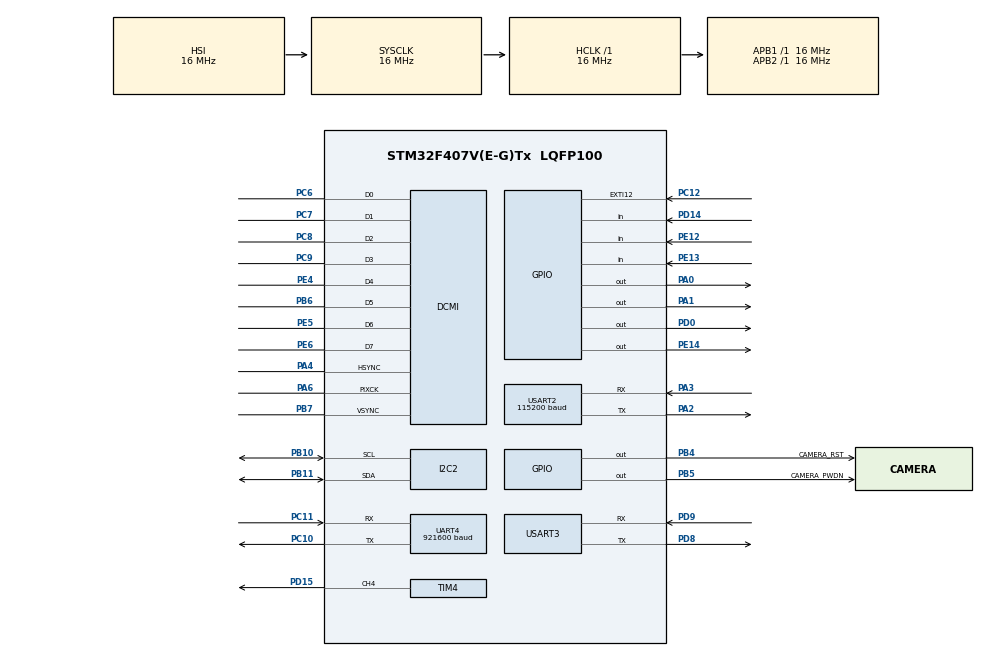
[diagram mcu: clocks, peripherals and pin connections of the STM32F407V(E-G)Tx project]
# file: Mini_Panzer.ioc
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DCMI.ExtendedDataMode=DCMI_EXTEND_DATA_8B
DCMI.SynchroMode=DCMI_SYNCHRO_HARDWARE
Dma.DCMI.2.Direction=DMA_PERIPH_TO_MEMORY
Dma.DCMI.2.FIFOMode=DMA_FIFOMODE_DISABLE
Dma.DCMI.2.Instance=DMA2_Stream1
Dma.DCMI.2.MemDataAlignment=DMA_MDATAALIGN_WORD
Dma.DCMI.2.MemInc=DMA_MINC_ENABLE
Dma.DCMI.2.Mode=DMA_NORMAL
Dma.DCMI.2.PeriphDataAlignment=DMA_PDATAALIGN_WORD
Dma.DCMI.2.PeriphInc=DMA_PINC_DISABLE
Dma.DCMI.2.Priority=DMA_PRIORITY_LOW
Dma.Request0=UART4_TX
Dma.Request1=UART4_RX
Dma.Request2=DCMI
Dma.UART4_RX.1.Direction=DMA_PERIPH_TO_MEMORY
Dma.UART4_RX.1.FIFOMode=DMA_FIFOMODE_DISABLE
Dma.UART4_RX.1.Instance=DMA1_Stream2
Dma.UART4_RX.1.MemDataAlignment=DMA_MDATAALIGN_BYTE
Dma.UART4_RX.1.MemInc=DMA_MINC_ENABLE
Dma.UART4_RX.1.Mode=DMA_NORMAL
Dma.UART4_RX.1.PeriphDataAlignment=DMA_PDATAALIGN_BYTE
Dma.UART4_RX.1.PeriphInc=DMA_PINC_DISABLE
Dma.UART4_RX.1.Priority=DMA_PRIORITY_VERY_HIGH
Dma.UART4_TX.0.Direction=DMA_MEMORY_TO_PERIPH
Dma.UART4_TX.0.FIFOMode=DMA_FIFOMODE_DISABLE
Dma.UART4_TX.0.Instance=DMA1_Stream4
Dma.UART4_TX.0.MemDataAlignment=DMA_MDATAALIGN_BYTE
Dma.UART4_TX.0.MemInc=DMA_MINC_ENABLE
Dma.UART4_TX.0.Mode=DMA_NORMAL
Dma.UART4_TX.0.PeriphDataAlignment=DMA_PDATAALIGN_BYTE
Dma.UART4_TX.0.PeriphInc=DMA_PINC_DISABLE
Dma.UART4_TX.0.Priority=DMA_PRIORITY_VERY_HIGH
FREERTOS.INCLUDE_xTaskAbortDelay=0
FREERTOS.INCLUDE_xTaskGetHandle=0
FREERTOS.MEMORY_ALLOCATION=0
FREERTOS.Tasks01=defaultTask,0,128,StartDefaultTask,Default
FREERTOS.configUSE_ALTERNATIVE_API=0
FREERTOS.configUSE_DAEMON_TASK_STARTUP_HOOK=0
I2C2.DutyCycle=I2C_DUTYCYCLE_2
Mcu.Family=STM32F4
Mcu.Name=STM32F407V(E-G)Tx
Mcu.Package=LQFP100
NVIC.DCMI_IRQn=true\:5\:0\:false\:false\:true\:true
NVIC.DMA1_Stream2_IRQn=true\:5\:0\:false\:false\:true\:true
NVIC.DMA1_Stream4_IRQn=true\:5\:0\:false\:false\:true\:true
NVIC.DMA2_Stream1_IRQn=true\:5\:0\:false\:false\:true\:true
NVIC.PriorityGroup=NVIC_PRIORITYGROUP_4
NVIC.UART4_IRQn=true\:5\:0\:false\:false\:true\:true
NVIC.USART2_IRQn=true\:5\:0\:false\:false\:true\:true
PA0-WKUP.GPIO_PuPd=GPIO_NOPULL
PA0-WKUP.GPIO_Speed=GPIO_SPEED_FREQ_VERY_HIGH
PA0-WKUP.PinState=GPIO_PIN_RESET
PA0-WKUP.Signal=GPIO_Output
PA1.GPIO_PuPd=GPIO_NOPULL
PA1.GPIO_Speed=GPIO_SPEED_FREQ_VERY_HIGH
PA1.PinState=GPIO_PIN_RESET
PA1.Signal=GPIO_Output
PA2.Mode=Asynchronous
PA2.Signal=USART2_TX
PA3.Mode=Asynchronous
PA3.Signal=USART2_RX
PA4.Mode=Slave_8_bits_External_Synchro
PA4.Signal=DCMI_HSYNC
PA6.Mode=Slave_8_bits_External_Synchro
PA6.Signal=DCMI_PIXCK
PB10.Mode=I2C
PB10.Signal=I2C2_SCL
PB11.Mode=I2C
PB11.Signal=I2C2_SDA
PB4.GPIO_Label=CAMERA_RST
PB4.GPIO_ModeDefaultOutputPP=GPIO_MODE_OUTPUT_PP
PB4.GPIO_PuPd=GPIO_NOPULL
PB4.PinState=GPIO_PIN_RESET
PB4.Signal=GPIO_Output
PB5.GPIO_Label=CAMERA_PWDN
PB5.Signal=GPIO_Output
PB6.Mode=Slave_8_bits_External_Synchro
PB6.Signal=DCMI_D5
PB7.Mode=Slave_8_bits_External_Synchro
PB7.Signal=DCMI_VSYNC
PC10.Mode=Asynchronous
PC10.Signal=UART4_TX
PC11.Mode=Asynchronous
PC11.Signal=UART4_RX
PC12.Signal=GPXTI12
PC6.Mode=Slave_8_bits_External_Synchro
PC6.Signal=DCMI_D0
PC7.Mode=Slave_8_bits_External_Synchro
PC7.Signal=DCMI_D1
PC8.Mode=Slave_8_bits_External_Synchro
PC8.Signal=DCMI_D2
PC9.Mode=Slave_8_bits_External_Synchro
PC9.Signal=DCMI_D3
PD0.Signal=GPIO_Output
PD14.Signal=GPIO_Input
PD15.Signal=S_TIM4_CH4
PD8.Mode=Asynchronous
PD8.Signal=USART3_TX
PD9.Mode=Asynchronous
PD9.Signal=USART3_RX
PE12.Signal=GPIO_Input
PE13.Signal=GPIO_Input
PE14.Signal=GPIO_Output
PE4.Mode=Slave_8_bits_External_Synchro
PE4.Signal=DCMI_D4
PE5.Mode=Slave_8_bits_External_Synchro
PE5.Signal=DCMI_D6
PE6.Mode=Slave_8_bits_External_Synchro
PE6.Signal=DCMI_D7
ProjectManager.HeapSize=0x200
ProjectManager.StackSize=0x400
ProjectManager.TargetToolchain=TrueSTUDIO
RCC.AHBFreq_Value=16000000
RCC.APB1Freq_Value=16000000
RCC.APB2Freq_Value=16000000
RCC.ClockTypeHCLK=RCC_CLOCKTYPE_HCLK
RCC.ClockTypePCLK1=RCC_CLOCKTYPE_PCLK1
RCC.ClockTypePCLK2=RCC_CLOCKTYPE_PCLK2
RCC.ClockTypeSysClk=RCC_CLOCKTYPE_SYSCLK
RCC.CortexFreq_Value=16000000
RCC.EnableExtClockForI2S=false
RCC.EnableHSE=false
RCC.EnableHSERTCDevisor=false
RCC.EnableLSE=false
RCC.EnableLSERTC=false
RCC.ExtClockEnable=false
RCC.HSEState=RCC_HSE_OFF
RCC.HSE_VALUE=25000000
RCC.HSIState=RCC_HSI_ON
RCC.HSI_VALUE=16000000
RCC.I2SEnable=false
RCC.IWDGEnable=false
RCC.LSE_VALUE=32768
RCC.LSIState=RCC_LSI_OFF
RCC.MCO1OutPutEnable=false
RCC.MCO2OutPutEnable=false
RCC.OscillatorTypeHSI=RCC_OSCILLATORTYPE_HSI
RCC.PLLSource=RCC_PLLSOURCE_HSI
RCC.PLLSourceVirtual=RCC_PLLSOURCE_HSI
RCC.PLLState=RCC_PLL_OFF
RCC.RNGEnable=false
RCC.RTCEnable=false
RCC.SDIOEnable=false
RCC.SYSCLKFreq_VALUE=16000000
RCC.USBFSEnable=false
RCC.USBHSEnable=false
RCC.VCOOutputFreq_Value=192000000
SH.S_TIM4_CH4.0=TIM4_CH4,PWM Generation4 CH4
TIM4.Channel-PWM\ Generation4\ CH4=TIM_CHANNEL_4
UART4.BaudRate=921600
UART4.VirtualMode=Asynchronous
USART2.BaudRate=115200
USART2.HwFlowCtl-Asynchronous=UART_HWCONTROL_NONE
USART2.OverSampling=UART_OVERSAMPLING_8
USART2.VirtualMode=VM_ASYNC
USART3.HwFlowCtl-Asynchronous=UART_HWCONTROL_NONE
USART3.VirtualMode=VM_ASYNC
VP_FREERTOS_VS_ENABLE.Mode=Enabled
board=Mini_Panzer

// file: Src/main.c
/**
  ******************************************************************************
  * File Name          : main.c
  * Description        : Main program body
  ******************************************************************************
  *
  * Copyright (c) 2017 STMicroelectronics International N.V.
  * All rights reserved.
  *
  * Redistribution and use in source and binary forms, with or without
  * modification, are permitted, provided that the following conditions are met:
  *
  * 1. Redistribution of source code must retain the above copyright notice,
  *    this list of conditions and the following disclaimer.
  * 2. Redistributions in binary form must reproduce the above copyright notice,
  *    this list of conditions and the following disclaimer in the documentation
  *    and/or other materials provided with the distribution.
  * 3. Neither the name of STMicroelectronics nor the names of other
  *    contributors to this software may be used to endorse or promote products
  *    derived from this software without specific written permission.
  * 4. This software, including modifications and/or derivative works of this
  *    software, must execute solely and exclusively on microcontroller or
  *    microprocessor devices manufactured by or for STMicroelectronics.
  * 5. Redistribution and use of this software other than as permitted under
  *    this license is void and will automatically terminate your rights under
  *    this license.
  *
  * THIS SOFTWARE IS PROVIDED BY STMICROELECTRONICS AND CONTRIBUTORS "AS IS"
  * AND ANY EXPRESS, IMPLIED OR STATUTORY WARRANTIES, INCLUDING, BUT NOT
  * LIMITED TO, THE IMPLIED WARRANTIES OF MERCHANTABILITY, FITNESS FOR A
  * PARTICULAR PURPOSE AND NON-INFRINGEMENT OF THIRD PARTY INTELLECTUAL PROPERTY
  * RIGHTS ARE DISCLAIMED TO THE FULLEST EXTENT PERMITTED BY LAW. IN NO EVENT
  * SHALL STMICROELECTRONICS OR CONTRIBUTORS BE LIABLE FOR ANY DIRECT, INDIRECT,
  * INCIDENTAL, SPECIAL, EXEMPLARY, OR CONSEQUENTIAL DAMAGES (INCLUDING, BUT NOT
  * LIMITED TO, PROCUREMENT OF SUBSTITUTE GOODS OR SERVICES; LOSS OF USE, DATA,
  * OR PROFITS; OR BUSINESS INTERRUPTION) HOWEVER CAUSED AND ON ANY THEORY OF
  * LIABILITY, WHETHER IN CONTRACT, STRICT LIABILITY, OR TORT (INCLUDING
  * NEGLIGENCE OR OTHERWISE) ARISING IN ANY WAY OUT OF THE USE OF THIS SOFTWARE,
  * EVEN IF ADVISED OF THE POSSIBILITY OF SUCH DAMAGE.
  *
  ******************************************************************************
  */
#include "main.h"
#include "stm32f4xx_hal.h"
#include "cmsis_os.h"

/* USER CODE BEGIN Includes */
#include "proj_inc/proj_main.h"
/* USER CODE END Includes */

DCMI_HandleTypeDef hdcmi;
DMA_HandleTypeDef hdma_dcmi;

I2C_HandleTypeDef hi2c2;

TIM_HandleTypeDef htim4;

UART_HandleTypeDef huart4;
UART_HandleTypeDef huart2;
UART_HandleTypeDef huart3;
DMA_HandleTypeDef hdma_uart4_tx;
DMA_HandleTypeDef hdma_uart4_rx;

osThreadId defaultTaskHandle;

/* USER CODE BEGIN PV */
/* Private variables ---------------------------------------------------------*/

/* USER CODE END PV */

void SystemClock_Config(void);
void Error_Handler(void);
static void MX_GPIO_Init(void);
static void MX_DMA_Init(void);
static void MX_I2C2_Init(void);
static void MX_TIM4_Init(void);
static void MX_USART2_UART_Init(void);
static void MX_USART3_UART_Init(void);
static void MX_UART4_Init(void);
static void MX_DCMI_Init(void);
void StartDefaultTask(void const * argument);

void HAL_TIM_MspPostInit(TIM_HandleTypeDef *htim);

/* USER CODE BEGIN PFP */
/* Private function prototypes -----------------------------------------------*/

/* USER CODE END PFP */

int main(void)
{

  /* MCU Configuration----------------------------------------------------------*/

  /* Reset of all peripherals, Initializes the Flash interface and the Systick. */
  HAL_Init();

  /* Configure the system clock */
  SystemClock_Config();

  /* Initialize all configured peripherals */
  MX_GPIO_Init();
  MX_DMA_Init();
  MX_I2C2_Init();
  MX_TIM4_Init();
  MX_USART2_UART_Init();
  MX_USART3_UART_Init();
  MX_UART4_Init();
  MX_DCMI_Init();

  /* USER CODE BEGIN 2 */
  GPIO_InitTypeDef      Wifi_GPIO_Init_t;
  Wifi_GPIO_Init_t.Pin       = GPIO_PIN_2 | GPIO_PIN_3;
  Wifi_GPIO_Init_t.Mode      = GPIO_MODE_AF_PP;//GPIO_MODE_AF_OD;//
  Wifi_GPIO_Init_t.Pull      = GPIO_NOPULL;//GPIO_PULLDOWN;//GPIO_PULLUP;//
  Wifi_GPIO_Init_t.Speed     = GPIO_SPEED_HIGH;
  Wifi_GPIO_Init_t.Alternate = GPIO_AF7_USART2;
  HAL_GPIO_Init(GPIOA,&Wifi_GPIO_Init_t);

  /* USER CODE END 2 */

  /* Create the thread(s) */
  /* definition and creation of defaultTask */
  osThreadDef(defaultTask, StartDefaultTask, osPriorityNormal, 0, 128);
  defaultTaskHandle = osThreadCreate(osThread(defaultTask), NULL);

  /* USER CODE BEGIN RTOS_THREADS */
  proj_main();
  /* USER CODE END RTOS_THREADS */

  /* Start scheduler */
  osKernelStart();

  /* We should never get here as control is now taken by the scheduler */

  /* Infinite loop */
  while (1)
  {

  }

}

/** System Clock Configuration
*/
void SystemClock_Config(void)
{

  RCC_OscInitTypeDef RCC_OscInitStruct;
  RCC_ClkInitTypeDef RCC_ClkInitStruct;

    /**Configure the main internal regulator output voltage
    */
  __HAL_RCC_PWR_CLK_ENABLE();

  __HAL_PWR_VOLTAGESCALING_CONFIG(PWR_REGULATOR_VOLTAGE_SCALE1);

    /**Initializes the CPU, AHB and APB busses clocks
    */
  RCC_OscInitStruct.OscillatorType = RCC_OSCILLATORTYPE_HSI;
  RCC_OscInitStruct.HSIState = RCC_HSI_ON;
  RCC_OscInitStruct.HSICalibrationValue = 16;
  RCC_OscInitStruct.PLL.PLLState = RCC_PLL_NONE;
  if (HAL_RCC_OscConfig(&RCC_OscInitStruct) != HAL_OK)
  {
    Error_Handler();
  }

    /**Initializes the CPU, AHB and APB busses clocks
    */
  RCC_ClkInitStruct.ClockType = RCC_CLOCKTYPE_HCLK|RCC_CLOCKTYPE_SYSCLK
                              |RCC_CLOCKTYPE_PCLK1|RCC_CLOCKTYPE_PCLK2;
  RCC_ClkInitStruct.SYSCLKSource = RCC_SYSCLKSOURCE_HSI;
  RCC_ClkInitStruct.AHBCLKDivider = RCC_SYSCLK_DIV1;
  RCC_ClkInitStruct.APB1CLKDivider = RCC_HCLK_DIV1;
  RCC_ClkInitStruct.APB2CLKDivider = RCC_HCLK_DIV1;

  if (HAL_RCC_ClockConfig(&RCC_ClkInitStruct, FLASH_LATENCY_0) != HAL_OK)
  {
    Error_Handler();
  }

    /**Configure the Systick interrupt time
    */
  HAL_SYSTICK_Config(HAL_RCC_GetHCLKFreq()/1000);

    /**Configure the Systick
    */
  HAL_SYSTICK_CLKSourceConfig(SYSTICK_CLKSOURCE_HCLK);

  /* SysTick_IRQn interrupt configuration */
  HAL_NVIC_SetPriority(SysTick_IRQn, 15, 0);
}

/* DCMI init function */
static void MX_DCMI_Init(void)
{

  hdcmi.Instance = DCMI;
  hdcmi.Init.SynchroMode = DCMI_SYNCHRO_HARDWARE;
  hdcmi.Init.PCKPolarity = DCMI_PCKPOLARITY_FALLING;
  hdcmi.Init.VSPolarity = DCMI_VSPOLARITY_LOW;
  hdcmi.Init.HSPolarity = DCMI_HSPOLARITY_LOW;
  hdcmi.Init.CaptureRate = DCMI_CR_ALL_FRAME;
  hdcmi.Init.ExtendedDataMode = DCMI_EXTEND_DATA_8B;
  hdcmi.Init.JPEGMode = DCMI_JPEG_DISABLE;
  if (HAL_DCMI_Init(&hdcmi) != HAL_OK)
  {
    Error_Handler();
  }

}

/* I2C2 init function */
static void MX_I2C2_Init(void)
{

  hi2c2.Instance = I2C2;
  hi2c2.Init.ClockSpeed = 100000;
  hi2c2.Init.DutyCycle = I2C_DUTYCYCLE_2;
  hi2c2.Init.OwnAddress1 = 0;
  hi2c2.Init.AddressingMode = I2C_ADDRESSINGMODE_7BIT;
  hi2c2.Init.DualAddressMode = I2C_DUALADDRESS_DISABLE;
  hi2c2.Init.OwnAddress2 = 0;
  hi2c2.Init.GeneralCallMode = I2C_GENERALCALL_DISABLE;
  hi2c2.Init.NoStretchMode = I2C_NOSTRETCH_DISABLE;
  if (HAL_I2C_Init(&hi2c2) != HAL_OK)
  {
    Error_Handler();
  }

}

/* TIM4 init function */
static void MX_TIM4_Init(void)
{

  TIM_MasterConfigTypeDef sMasterConfig;
  TIM_OC_InitTypeDef sConfigOC;

  htim4.Instance = TIM4;
  htim4.Init.Prescaler = 0;
  htim4.Init.CounterMode = TIM_COUNTERMODE_UP;
  htim4.Init.Period = 0;
  htim4.Init.ClockDivision = TIM_CLOCKDIVISION_DIV1;
  if (HAL_TIM_PWM_Init(&htim4) != HAL_OK)
  {
    Error_Handler();
  }

  sMasterConfig.MasterOutputTrigger = TIM_TRGO_RESET;
  sMasterConfig.MasterSlaveMode = TIM_MASTERSLAVEMODE_DISABLE;
  if (HAL_TIMEx_MasterConfigSynchronization(&htim4, &sMasterConfig) != HAL_OK)
  {
    Error_Handler();
  }

  sConfigOC.OCMode = TIM_OCMODE_PWM1;
  sConfigOC.Pulse = 0;
  sConfigOC.OCPolarity = TIM_OCPOLARITY_HIGH;
  sConfigOC.OCFastMode = TIM_OCFAST_DISABLE;
  if (HAL_TIM_PWM_ConfigChannel(&htim4, &sConfigOC, TIM_CHANNEL_4) != HAL_OK)
  {
    Error_Handler();
  }

  HAL_TIM_MspPostInit(&htim4);

}

/* UART4 init function */
static void MX_UART4_Init(void)
{

  huart4.Instance = UART4;
  huart4.Init.BaudRate = 921600;
  huart4.Init.WordLength = UART_WORDLENGTH_8B;
  huart4.Init.StopBits = UART_STOPBITS_1;
  huart4.Init.Parity = UART_PARITY_NONE;
  huart4.Init.Mode = UART_MODE_TX_RX;
  huart4.Init.HwFlowCtl = UART_HWCONTROL_NONE;
  huart4.Init.OverSampling = UART_OVERSAMPLING_16;
  if (HAL_UART_Init(&huart4) != HAL_OK)
  {
    Error_Handler();
  }

}

/* USART2 init function */
static void MX_USART2_UART_Init(void)
{

  huart2.Instance = USART2;
  huart2.Init.BaudRate = 115200;
  huart2.Init.WordLength = UART_WORDLENGTH_8B;
  huart2.Init.StopBits = UART_STOPBITS_1;
  huart2.Init.Parity = UART_PARITY_NONE;
  huart2.Init.Mode = UART_MODE_TX_RX;
  huart2.Init.HwFlowCtl = UART_HWCONTROL_NONE;
  huart2.Init.OverSampling = UART_OVERSAMPLING_8;
  if (HAL_UART_Init(&huart2) != HAL_OK)
  {
    Error_Handler();
  }

}

/* USART3 init function */
static void MX_USART3_UART_Init(void)
{

  huart3.Instance = USART3;
  huart3.Init.BaudRate = 115200;
  huart3.Init.WordLength = UART_WORDLENGTH_8B;
  huart3.Init.StopBits = UART_STOPBITS_1;
  huart3.Init.Parity = UART_PARITY_NONE;
  huart3.Init.Mode = UART_MODE_TX_RX;
  huart3.Init.HwFlowCtl = UART_HWCONTROL_NONE;
  huart3.Init.OverSampling = UART_OVERSAMPLING_16;
  if (HAL_UART_Init(&huart3) != HAL_OK)
  {
    Error_Handler();
  }

}

static void MX_DMA_Init(void)
{
  /* DMA controller clock enable */
  __HAL_RCC_DMA1_CLK_ENABLE();
  __HAL_RCC_DMA2_CLK_ENABLE();

  /* DMA interrupt init */
  /* DMA1_Stream2_IRQn interrupt configuration */
  HAL_NVIC_SetPriority(DMA1_Stream2_IRQn, 5, 0);
  HAL_NVIC_EnableIRQ(DMA1_Stream2_IRQn);
  /* DMA1_Stream4_IRQn interrupt configuration */
  HAL_NVIC_SetPriority(DMA1_Stream4_IRQn, 5, 0);
  HAL_NVIC_EnableIRQ(DMA1_Stream4_IRQn);
  /* DMA2_Stream1_IRQn interrupt configuration */
  HAL_NVIC_SetPriority(DMA2_Stream1_IRQn, 5, 0);
  HAL_NVIC_EnableIRQ(DMA2_Stream1_IRQn);

}

/** Configure pins as
        * Analog
        * Input
        * Output
        * EVENT_OUT
        * EXTI
*/
static void MX_GPIO_Init(void)
{

  GPIO_InitTypeDef GPIO_InitStruct;

  /* GPIO Ports Clock Enable */
  __HAL_RCC_GPIOE_CLK_ENABLE();
  __HAL_RCC_GPIOA_CLK_ENABLE();
  __HAL_RCC_GPIOB_CLK_ENABLE();
  __HAL_RCC_GPIOD_CLK_ENABLE();
  __HAL_RCC_GPIOC_CLK_ENABLE();

  /*Configure GPIO pin Output Level */
  HAL_GPIO_WritePin(GPIOA, GPIO_PIN_0|GPIO_PIN_1, GPIO_PIN_RESET);

  /*Configure GPIO pin Output Level */
  HAL_GPIO_WritePin(GPIOE, GPIO_PIN_14, GPIO_PIN_RESET);

  /*Configure GPIO pin Output Level */
  HAL_GPIO_WritePin(GPIOD, GPIO_PIN_0, GPIO_PIN_RESET);

  /*Configure GPIO pin Output Level */
  HAL_GPIO_WritePin(GPIOB, GPIO_PIN_4|GPIO_PIN_5, GPIO_PIN_RESET);

  /*Configure GPIO pins : PA0 PA1 */
  GPIO_InitStruct.Pin = GPIO_PIN_0|GPIO_PIN_1;
  GPIO_InitStruct.Mode = GPIO_MODE_OUTPUT_PP;
  GPIO_InitStruct.Pull = GPIO_NOPULL;
  GPIO_InitStruct.Speed = GPIO_SPEED_FREQ_VERY_HIGH;
  HAL_GPIO_Init(GPIOA, &GPIO_InitStruct);

  /*Configure GPIO pins : PE12 PE13 */
  GPIO_InitStruct.Pin = GPIO_PIN_12|GPIO_PIN_13;
  GPIO_InitStruct.Mode = GPIO_MODE_INPUT;
  GPIO_InitStruct.Pull = GPIO_NOPULL;
  HAL_GPIO_Init(GPIOE, &GPIO_InitStruct);

  /*Configure GPIO pin : PE14 */
  GPIO_InitStruct.Pin = GPIO_PIN_14;
  GPIO_InitStruct.Mode = GPIO_MODE_OUTPUT_PP;
  GPIO_InitStruct.Pull = GPIO_NOPULL;
  GPIO_InitStruct.Speed = GPIO_SPEED_FREQ_LOW;
  HAL_GPIO_Init(GPIOE, &GPIO_InitStruct);

  /*Configure GPIO pin : PD14 */
  GPIO_InitStruct.Pin = GPIO_PIN_14;
  GPIO_InitStruct.Mode = GPIO_MODE_INPUT;
  GPIO_InitStruct.Pull = GPIO_NOPULL;
  HAL_GPIO_Init(GPIOD, &GPIO_InitStruct);

  /*Configure GPIO pin : PC12 */
  GPIO_InitStruct.Pin = GPIO_PIN_12;
  GPIO_InitStruct.Mode = GPIO_MODE_IT_RISING;
  GPIO_InitStruct.Pull = GPIO_NOPULL;
  HAL_GPIO_Init(GPIOC, &GPIO_InitStruct);

  /*Configure GPIO pin : PD0 */
  GPIO_InitStruct.Pin = GPIO_PIN_0;
  GPIO_InitStruct.Mode = GPIO_MODE_OUTPUT_PP;
  GPIO_InitStruct.Pull = GPIO_NOPULL;
  GPIO_InitStruct.Speed = GPIO_SPEED_FREQ_LOW;
  HAL_GPIO_Init(GPIOD, &GPIO_InitStruct);

  /*Configure GPIO pins : PB4 PB5 */
  GPIO_InitStruct.Pin = GPIO_PIN_4|GPIO_PIN_5;
  GPIO_InitStruct.Mode = GPIO_MODE_OUTPUT_PP;
  GPIO_InitStruct.Pull = GPIO_NOPULL;
  GPIO_InitStruct.Speed = GPIO_SPEED_FREQ_LOW;
  HAL_GPIO_Init(GPIOB, &GPIO_InitStruct);

}

/* StartDefaultTask function */
void StartDefaultTask(void const * argument)
{

  for(;;)
  {
    osDelay(1);
  }
}

void Error_Handler(void)
{
  while(1)
  {
  }
}

/************************ (C) COPYRIGHT STMicroelectronics *****END OF FILE****/
